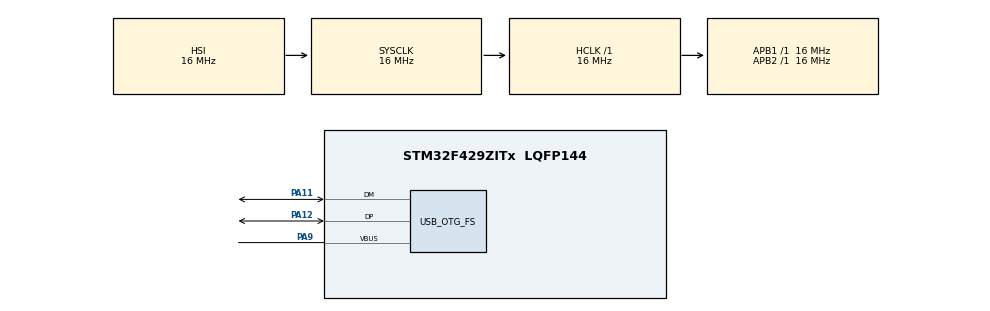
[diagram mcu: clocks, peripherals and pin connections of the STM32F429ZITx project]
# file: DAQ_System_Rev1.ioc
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FATFS._FS_EXFAT=1
FATFS._MAX_SS=4096
FATFS._USE_LFN=2
FREERTOS.Tasks01=defaultTask,24,128,StartDefaultTask,Default,NULL,Dynamic,NULL,NULL
Mcu.Family=STM32F4
Mcu.Name=STM32F429ZITx
Mcu.Package=LQFP144
NVIC.OTG_FS_IRQn=true\:15\:0\:true\:false\:true\:true\:false\:true\:true
NVIC.PriorityGroup=NVIC_PRIORITYGROUP_4
NVIC.TIM6_DAC_IRQn=true\:15\:0\:false\:false\:true\:false\:false\:true\:true
NVIC.TimeBase=TIM6_DAC_IRQn
NVIC.TimeBaseIP=TIM6
PA11.Mode=Host_Only
PA11.Signal=USB_OTG_FS_DM
PA12.Mode=Host_Only
PA12.Signal=USB_OTG_FS_DP
PA9.Mode=Activate_VBUS
PA9.Signal=USB_OTG_FS_VBUS
ProjectManager.HeapSize=0x200
ProjectManager.StackSize=0x400
ProjectManager.TargetToolchain=STM32CubeIDE
RCC.AHBFreq_Value=16000000
RCC.APB1Freq_Value=16000000
RCC.APB2Freq_Value=16000000
RCC.CortexFreq_Value=16000000
RCC.HSE_VALUE=25000000
RCC.HSI_VALUE=16000000
RCC.LSE_VALUE=32768
RCC.PLLSource=RCC_PLLSOURCE_HSI
RCC.PLLSourceVirtualString=RCC_PLLSOURCE_HSI
RCC.SYSCLKFreq_VALUE=16000000
RCC.VCOOutputFreq_Value=192000000
USB_HOST.USBH_HandleTypeDef-MSC_FS=hUsbHostFS
USB_HOST.USBH_PROCESS_PRIO-MSC_FS=osPriorityNormal
USB_HOST.USBH_PROCESS_STACK_SIZE-MSC_FS=1024
USB_HOST.VirtualModeFS=Msc
USB_OTG_FS.VirtualMode=Host_Only
USB_OTG_FS.phy_itface=HCD_PHY_EMBEDDED
VP_FATFS_VS_USB.Mode=USB
VP_FREERTOS_VS_CMSIS_V2.Mode=CMSIS_V2
VP_SYS_VS_tim6.Mode=TIM6
VP_USB_HOST_VS_USB_HOST_MSC_FS.Mode=MSC_FS
board=custom

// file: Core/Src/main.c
/* USER CODE BEGIN Header */
/**
  ******************************************************************************
  * @file           : main.c
  * @brief          : Main program body
  ******************************************************************************
  * @attention
  *
  * Copyright (c) 2024 STMicroelectronics.
  * All rights reserved.
  *
  * This software is licensed under terms that can be found in the LICENSE file
  * in the root directory of this software component.
  * If no LICENSE file comes with this software, it is provided AS-IS.
  *
  ******************************************************************************
  */
/* USER CODE END Header */
#include "main.h"
#include "cmsis_os.h"
#include "fatfs.h"
#include "usb_host.h"

/* USER CODE BEGIN Includes */
extern int to_unmount;
extern int to_log;

/* USER CODE END Includes */

/* Definitions for defaultTask */
osThreadId_t defaultTaskHandle;
const osThreadAttr_t defaultTask_attributes = {
  .name = "defaultTask",
  .stack_size = 128 * 20,
  .priority = (osPriority_t) osPriorityNormal,
};

void SystemClock_Config(void);
static void MX_GPIO_Init(void);
void StartDefaultTask(void *argument);

int main(void)
{

  /* MCU Configuration--------------------------------------------------------*/

  /* Reset of all peripherals, Initializes the Flash interface and the Systick. */
  HAL_Init();

  /* Configure the system clock */
  SystemClock_Config();

  /* Initialize all configured peripherals */
  MX_GPIO_Init();
  MX_FATFS_Init();
  /* USER CODE BEGIN 2 */
  NVIC_SetPriorityGrouping( 0 );
  /* USER CODE END 2 */

  /* Init scheduler */
  osKernelInitialize();

  /* Create the thread(s) */
  /* creation of defaultTask */
  defaultTaskHandle = osThreadNew(StartDefaultTask, NULL, &defaultTask_attributes);

  /* Start scheduler */
  osKernelStart();

  /* We should never get here as control is now taken by the scheduler */

  /* Infinite loop */
  while (1)
  {

  }
}

void SystemClock_Config(void)
{
  RCC_OscInitTypeDef RCC_OscInitStruct = {0};
  RCC_ClkInitTypeDef RCC_ClkInitStruct = {0};

  /** Configure the main internal regulator output voltage
  */
  __HAL_RCC_PWR_CLK_ENABLE();
  __HAL_PWR_VOLTAGESCALING_CONFIG(PWR_REGULATOR_VOLTAGE_SCALE3);

  /** Initializes the RCC Oscillators according to the specified parameters
  * in the RCC_OscInitTypeDef structure.
  */
  RCC_OscInitStruct.OscillatorType = RCC_OSCILLATORTYPE_HSI;
  RCC_OscInitStruct.HSIState = RCC_HSI_ON;
  RCC_OscInitStruct.HSICalibrationValue = RCC_HSICALIBRATION_DEFAULT;
  RCC_OscInitStruct.PLL.PLLState = RCC_PLL_ON;
  RCC_OscInitStruct.PLL.PLLSource = RCC_PLLSOURCE_HSI;
  RCC_OscInitStruct.PLL.PLLM = 16;
  RCC_OscInitStruct.PLL.PLLN = 192;
  RCC_OscInitStruct.PLL.PLLP = RCC_PLLP_DIV2;
  RCC_OscInitStruct.PLL.PLLQ = 4;
  if (HAL_RCC_OscConfig(&RCC_OscInitStruct) != HAL_OK)
  {
    Error_Handler();
  }

  /** Initializes the CPU, AHB and APB buses clocks
  */
  RCC_ClkInitStruct.ClockType = RCC_CLOCKTYPE_HCLK|RCC_CLOCKTYPE_SYSCLK
                              |RCC_CLOCKTYPE_PCLK1|RCC_CLOCKTYPE_PCLK2;
  RCC_ClkInitStruct.SYSCLKSource = RCC_SYSCLKSOURCE_HSI;
  RCC_ClkInitStruct.AHBCLKDivider = RCC_SYSCLK_DIV1;
  RCC_ClkInitStruct.APB1CLKDivider = RCC_HCLK_DIV1;
  RCC_ClkInitStruct.APB2CLKDivider = RCC_HCLK_DIV1;

  if (HAL_RCC_ClockConfig(&RCC_ClkInitStruct, FLASH_LATENCY_0) != HAL_OK)
  {
    Error_Handler();
  }
}

static void MX_GPIO_Init(void)
{

  /* GPIO Ports Clock Enable */
  __HAL_RCC_GPIOA_CLK_ENABLE();

}

void StartDefaultTask(void *argument)
{
  /* init code for USB_HOST */
  MX_USB_HOST_Init();
  /* USER CODE BEGIN 5 */
  /* Infinite loop */
  for (;;) {
	  if(to_log == 1) {
		Mount_USB();

			Check_USB_Details();   // check space details

			Scan_USB("/");   // scan for files and directories

			Create_File("/ROOTFILE.txt");
			Write_File("/ROOTFILE.txt", "This data should be in root file\n");

			Create_Dir("/DIR1");
			Create_File("/DIR1/DIR1FILE.txt");
			Write_File("/DIR1/DIR1FILE.txt", "This data should be in DIR1 file\n");

			Create_Dir("/DIR2");
			Create_Dir("/DIR2/SUBDIR1");
			Create_File("/DIR2/SUBDIR1/DIR2FILE.txt");
			Write_File("/DIR2/SUBDIR1/DIR2FILE.txt", "This data should be in DIR2/SUBDIR1 file\n as i have nothing better to write/n so i just wrote this\n");

			Update_File("/ROOTFILE.txt", "This updated data must be in second line of Root File\n");
			to_log = 0;

          } else if (to_unmount == 1) {
        	  Unmount_USB();
              to_unmount = 0;
          }
      }
  /* USER CODE END 5 */
}

void HAL_TIM_PeriodElapsedCallback(TIM_HandleTypeDef *htim)
{
  if (htim->Instance == TIM6) {
    HAL_IncTick();
  }
}

void Error_Handler(void)
{
  __disable_irq();
  while (1)
  {
  }
}
